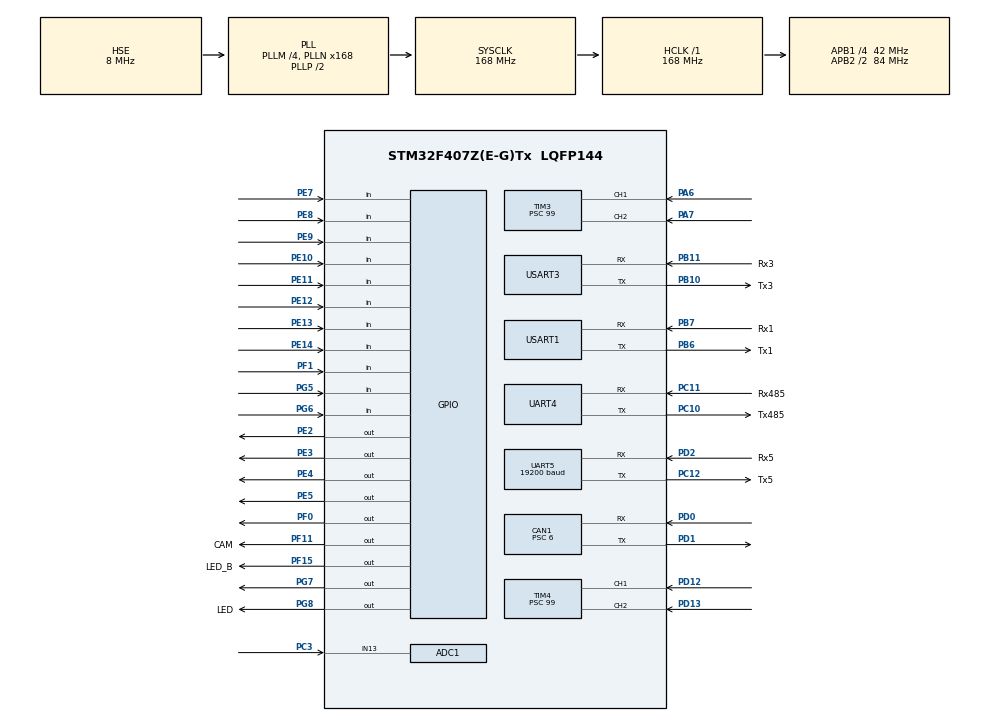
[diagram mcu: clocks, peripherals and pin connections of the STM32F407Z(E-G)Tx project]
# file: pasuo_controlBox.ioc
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ADC1.Channel-0\#ChannelRegularConversion=ADC_CHANNEL_13
ADC1.NbrOfConversionFlag=1
ADC1.Rank-0\#ChannelRegularConversion=1
ADC1.SamplingTime-0\#ChannelRegularConversion=ADC_SAMPLETIME_3CYCLES
ADC1.master=1
CAN1.BS1=CAN_BS1_6TQ
CAN1.BS2=CAN_BS2_7TQ
CAN1.CalculateTimeQuantum=142.85714285714286
CAN1.Prescaler=6
Dma.Request0=USART3_RX
Dma.Request1=USART3_TX
Dma.USART3_RX.0.Direction=DMA_PERIPH_TO_MEMORY
Dma.USART3_RX.0.FIFOMode=DMA_FIFOMODE_DISABLE
Dma.USART3_RX.0.Instance=DMA1_Stream1
Dma.USART3_RX.0.MemDataAlignment=DMA_MDATAALIGN_BYTE
Dma.USART3_RX.0.MemInc=DMA_MINC_ENABLE
Dma.USART3_RX.0.Mode=DMA_CIRCULAR
Dma.USART3_RX.0.PeriphDataAlignment=DMA_PDATAALIGN_BYTE
Dma.USART3_RX.0.PeriphInc=DMA_PINC_DISABLE
Dma.USART3_RX.0.Priority=DMA_PRIORITY_LOW
Dma.USART3_TX.1.Direction=DMA_MEMORY_TO_PERIPH
Dma.USART3_TX.1.FIFOMode=DMA_FIFOMODE_DISABLE
Dma.USART3_TX.1.Instance=DMA1_Stream3
Dma.USART3_TX.1.MemDataAlignment=DMA_MDATAALIGN_BYTE
Dma.USART3_TX.1.MemInc=DMA_MINC_ENABLE
Dma.USART3_TX.1.Mode=DMA_NORMAL
Dma.USART3_TX.1.PeriphDataAlignment=DMA_PDATAALIGN_BYTE
Dma.USART3_TX.1.PeriphInc=DMA_PINC_DISABLE
Dma.USART3_TX.1.Priority=DMA_PRIORITY_LOW
FREERTOS.Tasks01=defaultTask,0,128,StartDefaultTask,Default,NULL,Dynamic,NULL,NULL
FREERTOS.configTOTAL_HEAP_SIZE=51200
IWDG.Prescaler=IWDG_PRESCALER_32
IWDG.Reload=1024
Mcu.Family=STM32F4
Mcu.Name=STM32F407Z(E-G)Tx
Mcu.Package=LQFP144
NVIC.CAN1_RX0_IRQn=true\:5\:0\:false\:false\:true\:true\:true\:true
NVIC.CAN1_RX1_IRQn=true\:5\:0\:false\:false\:true\:true\:true\:true
NVIC.CAN1_TX_IRQn=true\:5\:0\:false\:false\:true\:true\:true\:true
NVIC.DMA1_Stream1_IRQn=true\:5\:0\:false\:false\:true\:true\:false\:true
NVIC.DMA1_Stream3_IRQn=true\:5\:0\:false\:false\:true\:true\:false\:true
NVIC.PriorityGroup=NVIC_PRIORITYGROUP_4
NVIC.TIM2_IRQn=true\:0\:0\:false\:false\:true\:false\:false\:true
NVIC.TIM3_IRQn=true\:5\:0\:false\:false\:true\:true\:true\:true
NVIC.TimeBase=TIM2_IRQn
NVIC.TimeBaseIP=TIM2
NVIC.UART4_IRQn=true\:5\:0\:false\:false\:true\:true\:true\:true
NVIC.UART5_IRQn=true\:5\:0\:false\:false\:true\:true\:true\:true
NVIC.USART1_IRQn=true\:5\:0\:false\:false\:true\:true\:true\:true
NVIC.USART3_IRQn=true\:5\:0\:false\:false\:true\:true\:true\:true
PA13.Mode=Serial_Wire
PA13.Signal=SYS_JTMS-SWDIO
PA14.Mode=Serial_Wire
PA14.Signal=SYS_JTCK-SWCLK
PA6.GPIO_PuPd=GPIO_PULLDOWN
PA6.GPIO_Speed=GPIO_SPEED_FREQ_VERY_HIGH
PA6.Signal=S_TIM3_CH1
PA7.GPIO_PuPd=GPIO_PULLDOWN
PA7.GPIO_Speed=GPIO_SPEED_FREQ_VERY_HIGH
PA7.Signal=S_TIM3_CH2
PB10.GPIO_Label=Tx3
PB10.GPIO_PuPd=GPIO_PULLDOWN
PB10.Mode=Asynchronous
PB10.Signal=USART3_TX
PB11.GPIO_Label=Rx3
PB11.GPIO_PuPd=GPIO_PULLDOWN
PB11.Mode=Asynchronous
PB11.Signal=USART3_RX
PB6.GPIO_Label=Tx1
PB6.GPIO_PuPd=GPIO_PULLDOWN
PB6.Mode=Asynchronous
PB6.Signal=USART1_TX
PB7.GPIO_Label=Rx1
PB7.GPIO_PuPd=GPIO_PULLDOWN
PB7.Mode=Asynchronous
PB7.Signal=USART1_RX
PC10.GPIO_Label=Tx485
PC10.Mode=Asynchronous
PC10.Signal=UART4_TX
PC11.GPIO_Label=Rx485
PC11.Mode=Asynchronous
PC11.Signal=UART4_RX
PC12.GPIO_Label=Tx5
PC12.GPIO_PuPd=GPIO_PULLUP
PC12.Mode=Asynchronous
PC12.Signal=UART5_TX
PC3.Signal=ADCx_IN13
PD0.GPIO_PuPd=GPIO_PULLDOWN
PD0.Mode=Master
PD0.Signal=CAN1_RX
PD1.GPIO_PuPd=GPIO_PULLDOWN
PD1.Mode=Master
PD1.Signal=CAN1_TX
PD12.GPIO_PuPd=GPIO_PULLDOWN
PD12.GPIO_Speed=GPIO_SPEED_FREQ_VERY_HIGH
PD12.Signal=S_TIM4_CH1
PD13.GPIO_PuPd=GPIO_PULLDOWN
PD13.GPIO_Speed=GPIO_SPEED_FREQ_VERY_HIGH
PD13.Signal=S_TIM4_CH2
PD2.GPIO_Label=Rx5
PD2.GPIO_PuPd=GPIO_PULLUP
PD2.Mode=Asynchronous
PD2.Signal=UART5_RX
PE10.GPIO_PuPd=GPIO_PULLUP
PE10.Signal=GPIO_Input
PE11.GPIO_PuPd=GPIO_PULLUP
PE11.Signal=GPIO_Input
PE12.GPIO_PuPd=GPIO_PULLUP
PE12.Signal=GPIO_Input
PE13.GPIO_PuPd=GPIO_PULLUP
PE13.Signal=GPIO_Input
PE14.GPIO_PuPd=GPIO_PULLUP
PE14.Signal=GPIO_Input
PE2.GPIO_PuPd=GPIO_PULLDOWN
PE2.GPIO_Speed=GPIO_SPEED_FREQ_MEDIUM
PE2.PinState=GPIO_PIN_RESET
PE2.Signal=GPIO_Output
PE3.GPIO_PuPd=GPIO_PULLDOWN
PE3.GPIO_Speed=GPIO_SPEED_FREQ_MEDIUM
PE3.Signal=GPIO_Output
PE4.GPIO_PuPd=GPIO_PULLDOWN
PE4.GPIO_Speed=GPIO_SPEED_FREQ_MEDIUM
PE4.Signal=GPIO_Output
PE5.GPIO_PuPd=GPIO_PULLDOWN
PE5.GPIO_Speed=GPIO_SPEED_FREQ_MEDIUM
PE5.Signal=GPIO_Output
PE7.GPIO_PuPd=GPIO_PULLUP
PE7.Signal=GPIO_Input
PE8.GPIO_PuPd=GPIO_PULLUP
PE8.Signal=GPIO_Input
PE9.GPIO_PuPd=GPIO_PULLUP
PE9.Signal=GPIO_Input
PF0.GPIO_PuPd=GPIO_PULLDOWN
PF0.Signal=GPIO_Output
PF1.GPIO_PuPd=GPIO_PULLDOWN
PF1.Signal=GPIO_Input
PF11.GPIO_Label=CAM
PF11.GPIO_PuPd=GPIO_PULLDOWN
PF11.GPIO_Speed=GPIO_SPEED_FREQ_VERY_HIGH
PF11.PinState=GPIO_PIN_RESET
PF11.Signal=GPIO_Output
PF15.GPIO_Label=LED_B
PF15.GPIO_PuPd=GPIO_PULLDOWN
PF15.Signal=GPIO_Output
PG5.GPIO_PuPd=GPIO_PULLUP
PG5.Signal=GPIO_Input
PG6.GPIO_PuPd=GPIO_PULLUP
PG6.Signal=GPIO_Input
PG7.GPIO_PuPd=GPIO_PULLDOWN
PG7.GPIO_Speed=GPIO_SPEED_FREQ_VERY_HIGH
PG7.Signal=GPIO_Output
PG8.GPIO_Label=LED
PG8.GPIO_PuPd=GPIO_PULLDOWN
PG8.Signal=GPIO_Output
PH0-OSC_IN.Mode=HSE-External-Oscillator
PH0-OSC_IN.Signal=RCC_OSC_IN
PH1-OSC_OUT.Mode=HSE-External-Oscillator
PH1-OSC_OUT.Signal=RCC_OSC_OUT
ProjectManager.HeapSize=0x2800
ProjectManager.StackSize=0x2800
ProjectManager.TargetToolchain=MDK-ARM V5.27
RCC.48MHZClocksFreq_Value=84000000
RCC.AHBFreq_Value=168000000
RCC.APB1CLKDivider=RCC_HCLK_DIV4
RCC.APB1Freq_Value=42000000
RCC.APB1TimFreq_Value=84000000
RCC.APB2CLKDivider=RCC_HCLK_DIV2
RCC.APB2Freq_Value=84000000
RCC.APB2TimFreq_Value=168000000
RCC.CortexFreq_Value=168000000
RCC.HCLKFreq_Value=168000000
RCC.HSE_VALUE=8000000
RCC.HSI_VALUE=16000000
RCC.LSE_VALUE=32768
RCC.PLLM=4
RCC.PLLN=168
RCC.PLLSourceVirtual=RCC_PLLSOURCE_HSE
RCC.SYSCLKFreq_VALUE=168000000
RCC.SYSCLKSource=RCC_SYSCLKSOURCE_PLLCLK
RCC.VCOOutputFreq_Value=336000000
SH.ADCx_IN13.0=ADC1_IN13,IN13
SH.S_TIM3_CH1.0=TIM3_CH1,Encoder_Interface
SH.S_TIM3_CH2.0=TIM3_CH2,Encoder_Interface
SH.S_TIM4_CH1.0=TIM4_CH1,Encoder_Interface
SH.S_TIM4_CH2.0=TIM4_CH2,Encoder_Interface
TIM3.Period=0xffff
TIM3.Prescaler=99
TIM4.Period=0xffff
TIM4.Prescaler=99
UART4.VirtualMode=Asynchronous
UART5.BaudRate=19200
UART5.VirtualMode=Asynchronous
USART1.VirtualMode=VM_ASYNC
USART3.VirtualMode=VM_ASYNC
VP_FREERTOS_VS_CMSIS_V1.Mode=CMSIS_V1
VP_IWDG_VS_IWDG.Mode=IWDG_Activate
VP_SYS_VS_tim2.Mode=TIM2
board=custom

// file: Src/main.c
/* USER CODE BEGIN Header */
/**
  ******************************************************************************
  * @file           : main.c
  * @brief          : Main program body
  ******************************************************************************
  * @attention
  *
  * <h2><center>&copy; Copyright (c) 2020 STMicroelectronics.
  * All rights reserved.</center></h2>
  *
  * This software component is licensed by ST under Ultimate Liberty license
  * SLA0044, the "License"; You may not use this file except in compliance with
  * the License. You may obtain a copy of the License at:
  *                             www.st.com/SLA0044
  *
  ******************************************************************************
  */
/* USER CODE END Header */

#include "main.h"
#include "cmsis_os.h"

/* USER CODE BEGIN Includes */
#include "user_task.h"
/* USER CODE END Includes */

ADC_HandleTypeDef hadc1;

CAN_HandleTypeDef hcan1;

IWDG_HandleTypeDef hiwdg;

TIM_HandleTypeDef htim3;
TIM_HandleTypeDef htim4;

UART_HandleTypeDef huart4;
UART_HandleTypeDef huart5;
UART_HandleTypeDef huart1;
UART_HandleTypeDef huart3;
DMA_HandleTypeDef hdma_usart3_rx;
DMA_HandleTypeDef hdma_usart3_tx;

osThreadId defaultTaskHandle;

void SystemClock_Config(void);
static void MX_GPIO_Init(void);
static void MX_DMA_Init(void);
static void MX_UART4_Init(void);
static void MX_UART5_Init(void);
static void MX_USART1_UART_Init(void);
static void MX_USART3_UART_Init(void);
static void MX_ADC1_Init(void);
static void MX_CAN1_Init(void);
static void MX_TIM3_Init(void);
static void MX_TIM4_Init(void);
static void MX_IWDG_Init(void);
void StartDefaultTask(void const * argument);

int main(void)
{

  /* MCU Configuration--------------------------------------------------------*/

  /* Reset of all peripherals, Initializes the Flash interface and the Systick. */
  HAL_Init();

  /* Configure the system clock */
  SystemClock_Config();

  /* Initialize all configured peripherals */
  MX_GPIO_Init();
  MX_DMA_Init();
  MX_UART4_Init();
  MX_UART5_Init();
  MX_USART1_UART_Init();
  MX_USART3_UART_Init();
  MX_ADC1_Init();
  MX_CAN1_Init();
  MX_TIM3_Init();
  MX_TIM4_Init();
  MX_IWDG_Init();

  /* Create the thread(s) */
  /* definition and creation of defaultTask */
  osThreadDef(defaultTask, StartDefaultTask, osPriorityNormal, 0, 128);
  defaultTaskHandle = osThreadCreate(osThread(defaultTask), NULL);

  /* Start scheduler */
  osKernelStart();

  /* We should never get here as control is now taken by the scheduler */
  /* Infinite loop */
  while (1)
  {

  }
}

void SystemClock_Config(void)
{
  RCC_OscInitTypeDef RCC_OscInitStruct = {0};
  RCC_ClkInitTypeDef RCC_ClkInitStruct = {0};

  /** Configure the main internal regulator output voltage
  */
  __HAL_RCC_PWR_CLK_ENABLE();
  __HAL_PWR_VOLTAGESCALING_CONFIG(PWR_REGULATOR_VOLTAGE_SCALE1);
  /** Initializes the CPU, AHB and APB busses clocks
  */
  RCC_OscInitStruct.OscillatorType = RCC_OSCILLATORTYPE_LSI|RCC_OSCILLATORTYPE_HSE;
  RCC_OscInitStruct.HSEState = RCC_HSE_ON;
  RCC_OscInitStruct.LSIState = RCC_LSI_ON;
  RCC_OscInitStruct.PLL.PLLState = RCC_PLL_ON;
  RCC_OscInitStruct.PLL.PLLSource = RCC_PLLSOURCE_HSE;
  RCC_OscInitStruct.PLL.PLLM = 4;
  RCC_OscInitStruct.PLL.PLLN = 168;
  RCC_OscInitStruct.PLL.PLLP = RCC_PLLP_DIV2;
  RCC_OscInitStruct.PLL.PLLQ = 4;
  if (HAL_RCC_OscConfig(&RCC_OscInitStruct) != HAL_OK)
  {
    Error_Handler();
  }
  /** Initializes the CPU, AHB and APB busses clocks
  */
  RCC_ClkInitStruct.ClockType = RCC_CLOCKTYPE_HCLK|RCC_CLOCKTYPE_SYSCLK
                              |RCC_CLOCKTYPE_PCLK1|RCC_CLOCKTYPE_PCLK2;
  RCC_ClkInitStruct.SYSCLKSource = RCC_SYSCLKSOURCE_PLLCLK;
  RCC_ClkInitStruct.AHBCLKDivider = RCC_SYSCLK_DIV1;
  RCC_ClkInitStruct.APB1CLKDivider = RCC_HCLK_DIV4;
  RCC_ClkInitStruct.APB2CLKDivider = RCC_HCLK_DIV2;

  if (HAL_RCC_ClockConfig(&RCC_ClkInitStruct, FLASH_LATENCY_5) != HAL_OK)
  {
    Error_Handler();
  }
}

static void MX_ADC1_Init(void)
{

  ADC_ChannelConfTypeDef sConfig = {0};

  /** Configure the global features of the ADC (Clock, Resolution, Data Alignment and number of conversion)
  */
  hadc1.Instance = ADC1;
  hadc1.Init.ClockPrescaler = ADC_CLOCK_SYNC_PCLK_DIV4;
  hadc1.Init.Resolution = ADC_RESOLUTION_12B;
  hadc1.Init.ScanConvMode = DISABLE;
  hadc1.Init.ContinuousConvMode = DISABLE;
  hadc1.Init.DiscontinuousConvMode = DISABLE;
  hadc1.Init.ExternalTrigConvEdge = ADC_EXTERNALTRIGCONVEDGE_NONE;
  hadc1.Init.ExternalTrigConv = ADC_SOFTWARE_START;
  hadc1.Init.DataAlign = ADC_DATAALIGN_RIGHT;
  hadc1.Init.NbrOfConversion = 1;
  hadc1.Init.DMAContinuousRequests = DISABLE;
  hadc1.Init.EOCSelection = ADC_EOC_SINGLE_CONV;
  if (HAL_ADC_Init(&hadc1) != HAL_OK)
  {
    Error_Handler();
  }
  /** Configure for the selected ADC regular channel its corresponding rank in the sequencer and its sample time.
  */
  sConfig.Channel = ADC_CHANNEL_13;
  sConfig.Rank = 1;
  sConfig.SamplingTime = ADC_SAMPLETIME_3CYCLES;
  if (HAL_ADC_ConfigChannel(&hadc1, &sConfig) != HAL_OK)
  {
    Error_Handler();
  }

}

static void MX_CAN1_Init(void)
{

  hcan1.Instance = CAN1;
  hcan1.Init.Prescaler = 6;
  hcan1.Init.Mode = CAN_MODE_NORMAL;
  hcan1.Init.SyncJumpWidth = CAN_SJW_1TQ;
  hcan1.Init.TimeSeg1 = CAN_BS1_6TQ;
  hcan1.Init.TimeSeg2 = CAN_BS2_7TQ;
  hcan1.Init.TimeTriggeredMode = DISABLE;
  hcan1.Init.AutoBusOff = DISABLE;
  hcan1.Init.AutoWakeUp = DISABLE;
  hcan1.Init.AutoRetransmission = DISABLE;
  hcan1.Init.ReceiveFifoLocked = DISABLE;
  hcan1.Init.TransmitFifoPriority = DISABLE;
  if (HAL_CAN_Init(&hcan1) != HAL_OK)
  {
    Error_Handler();
  }

}

static void MX_IWDG_Init(void)
{

  hiwdg.Instance = IWDG;
  hiwdg.Init.Prescaler = IWDG_PRESCALER_32;
  hiwdg.Init.Reload = 1024;
  if (HAL_IWDG_Init(&hiwdg) != HAL_OK)
  {
    Error_Handler();
  }

}

static void MX_TIM3_Init(void)
{

  TIM_Encoder_InitTypeDef sConfig = {0};
  TIM_MasterConfigTypeDef sMasterConfig = {0};

  htim3.Instance = TIM3;
  htim3.Init.Prescaler = 99;
  htim3.Init.CounterMode = TIM_COUNTERMODE_UP;
  htim3.Init.Period = 0xffff;
  htim3.Init.ClockDivision = TIM_CLOCKDIVISION_DIV1;
  htim3.Init.AutoReloadPreload = TIM_AUTORELOAD_PRELOAD_DISABLE;
  sConfig.EncoderMode = TIM_ENCODERMODE_TI1;
  sConfig.IC1Polarity = TIM_ICPOLARITY_RISING;
  sConfig.IC1Selection = TIM_ICSELECTION_DIRECTTI;
  sConfig.IC1Prescaler = TIM_ICPSC_DIV1;
  sConfig.IC1Filter = 0;
  sConfig.IC2Polarity = TIM_ICPOLARITY_RISING;
  sConfig.IC2Selection = TIM_ICSELECTION_DIRECTTI;
  sConfig.IC2Prescaler = TIM_ICPSC_DIV1;
  sConfig.IC2Filter = 0;
  if (HAL_TIM_Encoder_Init(&htim3, &sConfig) != HAL_OK)
  {
    Error_Handler();
  }
  sMasterConfig.MasterOutputTrigger = TIM_TRGO_RESET;
  sMasterConfig.MasterSlaveMode = TIM_MASTERSLAVEMODE_DISABLE;
  if (HAL_TIMEx_MasterConfigSynchronization(&htim3, &sMasterConfig) != HAL_OK)
  {
    Error_Handler();
  }

}

static void MX_TIM4_Init(void)
{

  TIM_Encoder_InitTypeDef sConfig = {0};
  TIM_MasterConfigTypeDef sMasterConfig = {0};

  htim4.Instance = TIM4;
  htim4.Init.Prescaler = 99;
  htim4.Init.CounterMode = TIM_COUNTERMODE_UP;
  htim4.Init.Period = 0xffff;
  htim4.Init.ClockDivision = TIM_CLOCKDIVISION_DIV1;
  htim4.Init.AutoReloadPreload = TIM_AUTORELOAD_PRELOAD_DISABLE;
  sConfig.EncoderMode = TIM_ENCODERMODE_TI1;
  sConfig.IC1Polarity = TIM_ICPOLARITY_RISING;
  sConfig.IC1Selection = TIM_ICSELECTION_DIRECTTI;
  sConfig.IC1Prescaler = TIM_ICPSC_DIV1;
  sConfig.IC1Filter = 0;
  sConfig.IC2Polarity = TIM_ICPOLARITY_RISING;
  sConfig.IC2Selection = TIM_ICSELECTION_DIRECTTI;
  sConfig.IC2Prescaler = TIM_ICPSC_DIV1;
  sConfig.IC2Filter = 0;
  if (HAL_TIM_Encoder_Init(&htim4, &sConfig) != HAL_OK)
  {
    Error_Handler();
  }
  sMasterConfig.MasterOutputTrigger = TIM_TRGO_RESET;
  sMasterConfig.MasterSlaveMode = TIM_MASTERSLAVEMODE_DISABLE;
  if (HAL_TIMEx_MasterConfigSynchronization(&htim4, &sMasterConfig) != HAL_OK)
  {
    Error_Handler();
  }

}

static void MX_UART4_Init(void)
{

  huart4.Instance = UART4;
  huart4.Init.BaudRate = 115200;
  huart4.Init.WordLength = UART_WORDLENGTH_8B;
  huart4.Init.StopBits = UART_STOPBITS_1;
  huart4.Init.Parity = UART_PARITY_NONE;
  huart4.Init.Mode = UART_MODE_TX_RX;
  huart4.Init.HwFlowCtl = UART_HWCONTROL_NONE;
  huart4.Init.OverSampling = UART_OVERSAMPLING_16;
  if (HAL_UART_Init(&huart4) != HAL_OK)
  {
    Error_Handler();
  }

}

static void MX_UART5_Init(void)
{

  huart5.Instance = UART5;
  huart5.Init.BaudRate = 19200;
  huart5.Init.WordLength = UART_WORDLENGTH_8B;
  huart5.Init.StopBits = UART_STOPBITS_1;
  huart5.Init.Parity = UART_PARITY_NONE;
  huart5.Init.Mode = UART_MODE_TX_RX;
  huart5.Init.HwFlowCtl = UART_HWCONTROL_NONE;
  huart5.Init.OverSampling = UART_OVERSAMPLING_16;
  if (HAL_UART_Init(&huart5) != HAL_OK)
  {
    Error_Handler();
  }

}

static void MX_USART1_UART_Init(void)
{

  huart1.Instance = USART1;
  huart1.Init.BaudRate = 115200;
  huart1.Init.WordLength = UART_WORDLENGTH_8B;
  huart1.Init.StopBits = UART_STOPBITS_1;
  huart1.Init.Parity = UART_PARITY_NONE;
  huart1.Init.Mode = UART_MODE_TX_RX;
  huart1.Init.HwFlowCtl = UART_HWCONTROL_NONE;
  huart1.Init.OverSampling = UART_OVERSAMPLING_16;
  if (HAL_UART_Init(&huart1) != HAL_OK)
  {
    Error_Handler();
  }

}

static void MX_USART3_UART_Init(void)
{

  huart3.Instance = USART3;
  huart3.Init.BaudRate = 115200;
  huart3.Init.WordLength = UART_WORDLENGTH_8B;
  huart3.Init.StopBits = UART_STOPBITS_1;
  huart3.Init.Parity = UART_PARITY_NONE;
  huart3.Init.Mode = UART_MODE_TX_RX;
  huart3.Init.HwFlowCtl = UART_HWCONTROL_NONE;
  huart3.Init.OverSampling = UART_OVERSAMPLING_16;
  if (HAL_UART_Init(&huart3) != HAL_OK)
  {
    Error_Handler();
  }

}

static void MX_DMA_Init(void)
{

  /* DMA controller clock enable */
  __HAL_RCC_DMA1_CLK_ENABLE();

  /* DMA interrupt init */
  /* DMA1_Stream1_IRQn interrupt configuration */
  HAL_NVIC_SetPriority(DMA1_Stream1_IRQn, 5, 0);
  HAL_NVIC_EnableIRQ(DMA1_Stream1_IRQn);
  /* DMA1_Stream3_IRQn interrupt configuration */
  HAL_NVIC_SetPriority(DMA1_Stream3_IRQn, 5, 0);
  HAL_NVIC_EnableIRQ(DMA1_Stream3_IRQn);

}

static void MX_GPIO_Init(void)
{
  GPIO_InitTypeDef GPIO_InitStruct = {0};

  /* GPIO Ports Clock Enable */
  __HAL_RCC_GPIOE_CLK_ENABLE();
  __HAL_RCC_GPIOF_CLK_ENABLE();
  __HAL_RCC_GPIOH_CLK_ENABLE();
  __HAL_RCC_GPIOC_CLK_ENABLE();
  __HAL_RCC_GPIOA_CLK_ENABLE();
  __HAL_RCC_GPIOB_CLK_ENABLE();
  __HAL_RCC_GPIOD_CLK_ENABLE();
  __HAL_RCC_GPIOG_CLK_ENABLE();

  /*Configure GPIO pin Output Level */
  HAL_GPIO_WritePin(GPIOE, GPIO_PIN_2|GPIO_PIN_3|GPIO_PIN_4|GPIO_PIN_5, GPIO_PIN_RESET);

  /*Configure GPIO pin Output Level */
  HAL_GPIO_WritePin(GPIOF, GPIO_PIN_0|CAM_Pin|LED_B_Pin, GPIO_PIN_RESET);

  /*Configure GPIO pin Output Level */
  HAL_GPIO_WritePin(GPIOG, GPIO_PIN_7|LED_Pin, GPIO_PIN_RESET);

  /*Configure GPIO pins : PE2 PE3 PE4 PE5 */
  GPIO_InitStruct.Pin = GPIO_PIN_2|GPIO_PIN_3|GPIO_PIN_4|GPIO_PIN_5;
  GPIO_InitStruct.Mode = GPIO_MODE_OUTPUT_PP;
  GPIO_InitStruct.Pull = GPIO_PULLDOWN;
  GPIO_InitStruct.Speed = GPIO_SPEED_FREQ_MEDIUM;
  HAL_GPIO_Init(GPIOE, &GPIO_InitStruct);

  /*Configure GPIO pins : PF0 LED_B_Pin */
  GPIO_InitStruct.Pin = GPIO_PIN_0|LED_B_Pin;
  GPIO_InitStruct.Mode = GPIO_MODE_OUTPUT_PP;
  GPIO_InitStruct.Pull = GPIO_PULLDOWN;
  GPIO_InitStruct.Speed = GPIO_SPEED_FREQ_LOW;
  HAL_GPIO_Init(GPIOF, &GPIO_InitStruct);

  /*Configure GPIO pin : PF1 */
  GPIO_InitStruct.Pin = GPIO_PIN_1;
  GPIO_InitStruct.Mode = GPIO_MODE_INPUT;
  GPIO_InitStruct.Pull = GPIO_PULLDOWN;
  HAL_GPIO_Init(GPIOF, &GPIO_InitStruct);

  /*Configure GPIO pin : CAM_Pin */
  GPIO_InitStruct.Pin = CAM_Pin;
  GPIO_InitStruct.Mode = GPIO_MODE_OUTPUT_PP;
  GPIO_InitStruct.Pull = GPIO_PULLDOWN;
  GPIO_InitStruct.Speed = GPIO_SPEED_FREQ_VERY_HIGH;
  HAL_GPIO_Init(CAM_GPIO_Port, &GPIO_InitStruct);

  /*Configure GPIO pins : PE7 PE8 PE9 PE10
                           PE11 PE12 PE13 PE14 */
  GPIO_InitStruct.Pin = GPIO_PIN_7|GPIO_PIN_8|GPIO_PIN_9|GPIO_PIN_10
                          |GPIO_PIN_11|GPIO_PIN_12|GPIO_PIN_13|GPIO_PIN_14;
  GPIO_InitStruct.Mode = GPIO_MODE_INPUT;
  GPIO_InitStruct.Pull = GPIO_PULLUP;
  HAL_GPIO_Init(GPIOE, &GPIO_InitStruct);

  /*Configure GPIO pins : PG5 PG6 */
  GPIO_InitStruct.Pin = GPIO_PIN_5|GPIO_PIN_6;
  GPIO_InitStruct.Mode = GPIO_MODE_INPUT;
  GPIO_InitStruct.Pull = GPIO_PULLUP;
  HAL_GPIO_Init(GPIOG, &GPIO_InitStruct);

  /*Configure GPIO pin : PG7 */
  GPIO_InitStruct.Pin = GPIO_PIN_7;
  GPIO_InitStruct.Mode = GPIO_MODE_OUTPUT_PP;
  GPIO_InitStruct.Pull = GPIO_PULLDOWN;
  GPIO_InitStruct.Speed = GPIO_SPEED_FREQ_VERY_HIGH;
  HAL_GPIO_Init(GPIOG, &GPIO_InitStruct);

  /*Configure GPIO pin : LED_Pin */
  GPIO_InitStruct.Pin = LED_Pin;
  GPIO_InitStruct.Mode = GPIO_MODE_OUTPUT_PP;
  GPIO_InitStruct.Pull = GPIO_PULLDOWN;
  GPIO_InitStruct.Speed = GPIO_SPEED_FREQ_LOW;
  HAL_GPIO_Init(LED_GPIO_Port, &GPIO_InitStruct);

}

void StartDefaultTask(void const * argument)
{
  /* USER CODE BEGIN 5 */
  /* Infinite loop */
	userTaskInit();
  for(;;)
  {
    osDelay(1);
  }
  /* USER CODE END 5 */
}

 /**
  * @brief  Period elapsed callback in non blocking mode
  * @note   This function is called  when TIM2 interrupt took place, inside
  * HAL_TIM_IRQHandler(). It makes a direct call to HAL_IncTick() to increment
  * a global variable "uwTick" used as application time base.
  * @param  htim : TIM handle
  * @retval None
  */
void HAL_TIM_PeriodElapsedCallback(TIM_HandleTypeDef *htim)
{
  if (htim->Instance == TIM2) {
    HAL_IncTick();
  }
}

void Error_Handler(void)
{
}

/************************ (C) COPYRIGHT STMicroelectronics *****END OF FILE****/
